# psoc4100smax register map
Vendor: Infineon Technologies; Series: PSOC4100Smax; File version: 1.0
CPU: CM0PLUS r0p1, little endian, MPU, no FPU, VTOR, 2 interrupt priority bits, 32 interrupts
Registers are 32-bit, read-write, reset 0x0 unless marked. A register's access mark holds for its fields unless they carry their own. Offsets are from the block's base; [hi:lo] are bit positions; lines under a group give offsets from that group; {n}, {i} and the like mark numbered series; 'fields as' and 'values as' point back to an identical list; <NAME> marks a mode.

## MSC0 (part 2 of 2) — MultiSense Controller
Base 0x40290000
Same registers: MSC1 0x402A0000
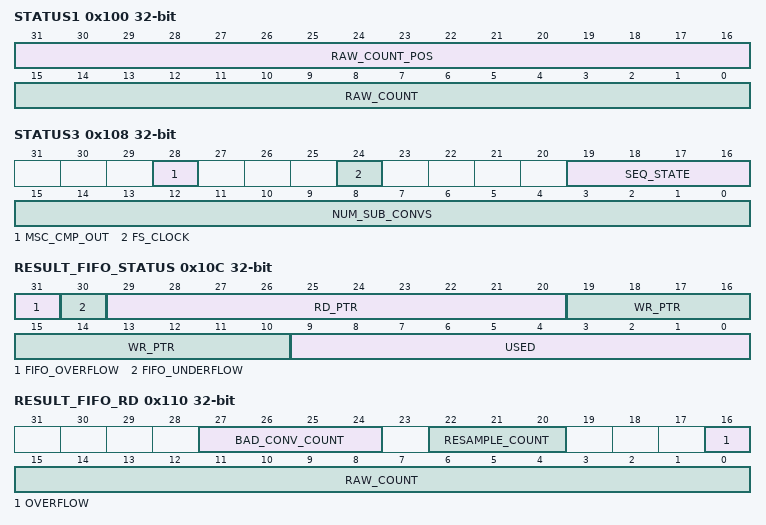
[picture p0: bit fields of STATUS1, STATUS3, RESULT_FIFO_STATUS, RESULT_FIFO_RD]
0x100 STATUS1 ro — General Status Register 1
  [31:16] RAW_COUNT_POS — Useful for determining component counts for positive and negative charge by subtracting from RAW_COUNT. When PHASE_MODE_SEL = FOUR_PHASE RAW_COUNT_POS: Counts during ph1/ph2 of SUB_CONV. When PHASE_MODE_SEL = TWO_PHASE RAW_COUNT_POS: Counts during ph0 of SUB_CONV. This counter increments whenever the Cref CAPDAC is balancing during the corresponding phases above. Note that digital non-overlap is ignored for the purposes of this count since balancing occurs irrespective of these settings. Hence the 'raw' phases (pre application of any digital non-overlap) are considered as the measurement window for this counter. Applicable for CIC1 and CIC2 mode. In CIC2 mode the count is determined by the value of the input to the first integrator stage (equivalent to CIC1 behaviour).
  [15:0] RAW_COUNT — Live current raw counter. For debug/test purposes. In normal operation, Firmware/DMA will typically read results from RESULT_FIFO_RD. Note that in CIC2 mode, this value gets updated at the decimation rate. When the SUB_SAMPLE interrupt is asserted, firmware could read this value before the next SUB_SAMPLE interrupt fires to debug sub-samples if desired.
0x104 STATUS2 ro — General Status Register 2
  [15:0] DEBUG_CONV_COUNT — Debug raw count for a particular conversion. Enabled only during a specified conversion of a sample (a specific chop phase). Only applicable for CIC1 mode. In CIC2 mode this counter remains zero.
0x108 STATUS3 ro — General Status Register 3
  [28] MSC_CMP_OUT — Output of main sensing comparator (synchronized). For debug/test purposes.
  [24] FS_CLOCK — Sense clock Fs control waveform. For debug/test purposes.
  [19:16] SEQ_STATE — MSC Sequencer FSM state.
    0=IDLE (N/A); 1=WAIT_DMA_WRITE (N/A); 2=LOAD_CONFIG (N/A); 3=WAIT_SCAN_START (N/A); 4=ASSERT_RDY (N/A); 5=WAIT_CONSENSUS (N/A); 6=INIT_CMOD (N/A); 7=INIT_SHORT (N/A); 8=PRO_OFFSET (N/A); 9=PRO_DUMMY (N/A); 10=PRO_WAIT (N/A); 11=SUB_CONV (N/A); 12=EPILOGUE (N/A); 13=WAIT_DMA_READ_NEW_SAMPLE (N/A); 14=WAIT_DMA_READ_EOF (N/A); 15=POST_SCAN (N/A)
  [15:0] NUM_SUB_CONVS — Number of sub-conversions remaining while in PRO_DUMMY and SUB_CONV.
0x10C RESULT_FIFO_STATUS ro
  [31] FIFO_OVERFLOW — Set if hardware attempts to write a RAW_COUNT (and associated metrics) to an already full result FIFO.
  [30] FIFO_UNDERFLOW — Hardware sets this field to '1', when reading from an empty FIFO (RESULT_FIFO_STATUS.USED is '0').
  [29:20] RD_PTR — Result FIFO read pointer: FIFO location from which data is read via AHB. Note: This functionality is intended for debugging purposes.
  [19:10] WR_PTR — Result FIFO write pointer: FIFO location at which a new data is written by the hardware. Note: This functionality is intended for debugging purposes.
  [9:0] USED — Number of used/occupied entries in the result FIFO. When '0', the FIFO is empty.
0x110 RESULT_FIFO_RD ro — Result FIFO Pointer
  [27:24] BAD_CONV_COUNT — Counter to indicate whether conversion of a sample is bad at the end of each chop phase. This is true if the comparator has not tripped by the end of EPILOGUE in a chop phase. BAD_CONV_COUNT can have a maximum value of 8 (based on largest legal NUM_CONV). If RESAMPLE_COUNT > 0 and BAD_CONV_COUNT = 0, this indicates that RESAMPLE_COUNT bad samples were encountered before this good sample was obtained. If RESAMPLE_COUNT > 0 and BAD_CONV_COUNT > 0, this indicates that all NUM_AUTO_RESAMPLE attempts have been executed and the final attempt had BAD_CONV_COUNT bad conversions. In this situation RESAMPLE_COUNT should equal NUM_AUTO_RESAMPLE.
  [22:20] RESAMPLE_COUNT — Counter indicating number of attempted re-samples (via NUM_AUTO_RESAMPLE) for this raw count. If RESAMPLE_COUNT = 0 and NUM_AUTO_RESAMPLE > 0, this raw count was obtained from the first sample attempt.
  [16] OVERFLOW — RAW_COUNT overflow.
  [15:0] RAW_COUNT — FILTER_MODE = CIC1: Accumulated raw count for a sample. FILTER_MODE = CIC2: Average value of all valid sub-samples over all conversions in a sample. Note that the hardware averaging capabilities are limited. See INTR.CIC2_ERROR - if this interrupt asserts it *may* be possible to firmware back calculate the correct average. See SCAN_CTL1.RAW_COUNT_MODE for overflow behaviour of RAW_COUNT.
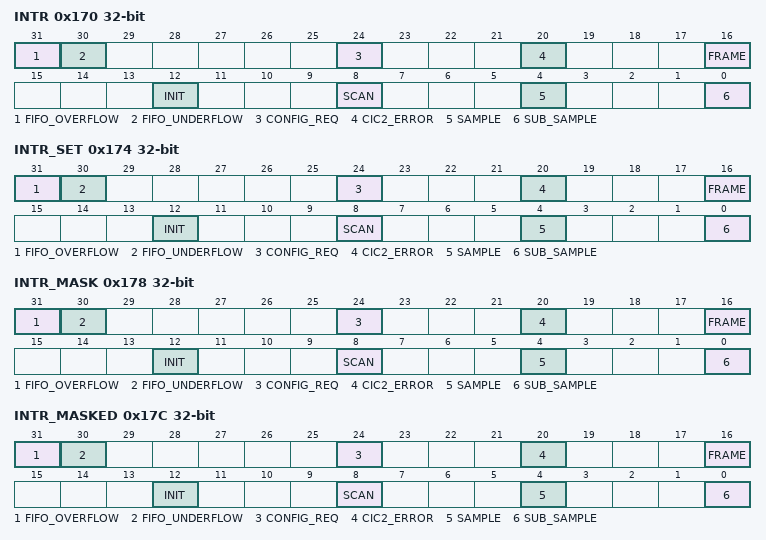
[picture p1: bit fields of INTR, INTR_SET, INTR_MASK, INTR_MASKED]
0x170 INTR — MSCv3 Interrupt Cause Register
  [31] FIFO_OVERFLOW write-1-clears — Result FIFO overflow condition.
  [30] FIFO_UNDERFLOW write-1-clears — Result FIFO underflow condition.
  [24] CONFIG_REQ write-1-clears — Request for scan configuration and scan start. The Sequencer FSM is entering WAIT_SCAN_START when this interrupt is raised. This interrupt can be used in CPU mode in a multi-channel scenario with external frame start to indicate to firmware that it is required to configure the channel and start a scan.
  [20] CIC2_ERROR write-1-clears — CIC2 error detected. This bit is set at the end of a sample if the number of valid CIC2 sub-samples is not one of [1,2,4,8,16]. At the end of a CIC2 sample, RESULT_FIFO_RD.RAW_COUNT contains the average of the valid sub-samples observed during that sample. The average is computed by a power of 2 shift as per below for the number of valid CIC2 samples observed: 0,1 -> no division (not a typical use case since an average of multiple sub-samples is desired) 2 -> divide by 2 3,4 -> divide by 4 5,6,7,8 -> divide by 8 9+ -> divide by 16 The RESULT_FIFO_RD.RAW_COUNT value is only the true average if the number of valid CIC2 sub-samples is [1,2,4,8,16]. However, in the cases of [3.4.5.6.9.10,11,12,13,14,15] firmware can back-calculate the real average from the computed average (RAW_COUNT) and the divisor used to compute that average (1,2,4,8,16 above) as follows assuming the number of valid sub-samples is known: Real_Average = Computed_Average*(Computed_Divider/NumSubSamples) If the number of sub-samples exceeds 16, this cannot be reliably computed due to internal hardware overflows.
  [16] FRAME write-1-clears — A single frame is complete.
  [12] INIT write-1-clears — Coarse initialisation complete. For debug purposes.
  [8] SCAN write-1-clears — A single scan is complete.
  [4] SAMPLE write-1-clears — A single sample is complete. For debug purposes.
  [0] SUB_SAMPLE write-1-clears — A valid CIC2 sub-sample is complete. To facilitate firmware averaging of sub-samples. For debug purposes.
0x174 INTR_SET — MSCv3 Interrupt Set Register
  [31] FIFO_OVERFLOW write-1-sets — Write with '1' to set corresponding bit in interrupt request register (a write of '0' has no effect).
  [30] FIFO_UNDERFLOW write-1-sets — Write with '1' to set corresponding bit in interrupt request register (a write of '0' has no effect).
  [24] CONFIG_REQ write-1-sets — Write with '1' to set corresponding bit in interrupt request register (a write of '0' has no effect).
  [20] CIC2_ERROR write-1-sets — Write with '1' to set corresponding bit in interrupt request register (a write of '0' has no effect).
  [16] FRAME write-1-sets — Write with '1' to set corresponding bit in interrupt request register (a write of '0' has no effect).
  [12] INIT write-1-sets — Write with '1' to set corresponding bit in interrupt request register (a write of '0' has no effect).
  [8] SCAN write-1-sets — Write with '1' to set corresponding bit in interrupt request register (a write of '0' has no effect).
  [4] SAMPLE write-1-sets — Write with '1' to set corresponding bit in interrupt request register (a write of '0' has no effect).
  [0] SUB_SAMPLE write-1-sets — Write with '1' to set corresponding bit in interrupt request register (a write of '0' has no effect).
0x178 INTR_MASK — MSCv3 Interrupt Mask Register
  [31] FIFO_OVERFLOW — Mask bit for corresponding bit in interrupt cause register.
  [30] FIFO_UNDERFLOW — Mask bit for corresponding bit in interrupt cause register.
  [24] CONFIG_REQ — Mask bit for corresponding bit in interrupt cause register.
  [20] CIC2_ERROR — Mask bit for corresponding bit in interrupt cause register.
  [16] FRAME — Mask bit for corresponding bit in interrupt cause register.
  [12] INIT — Mask bit for corresponding bit in interrupt cause register.
  [8] SCAN — Mask bit for corresponding bit in interrupt cause register.
  [4] SAMPLE — Mask bit for corresponding bit in interrupt cause register.
  [0] SUB_SAMPLE — Mask bit for corresponding bit in interrupt cause register.
0x17C INTR_MASKED ro — MSCv3 Interrupt Masked Register
  [31] FIFO_OVERFLOW — Logical AND of corresponding INTR and INTR_MASK bits.
  [30] FIFO_UNDERFLOW — Logical AND of corresponding INTR and INTR_MASK bits.
  [24] CONFIG_REQ — Logical AND of corresponding INTR and INTR_MASK bits.
  [20] CIC2_ERROR — Logical AND of corresponding INTR and INTR_MASK bits.
  [16] FRAME — Logical AND of corresponding INTR and INTR_MASK bits.
  [12] INIT — Logical AND of corresponding INTR and INTR_MASK bits.
  [8] SCAN — Logical AND of corresponding INTR and INTR_MASK bits.
  [4] SAMPLE — Logical AND of corresponding INTR and INTR_MASK bits.
  [0] SUB_SAMPLE — Logical AND of corresponding INTR and INTR_MASK bits.
0x180 INTR_LP — Low Power Interrupt Cause Register
  [0] WAKEUP write-1-clears — LP-AoC has detected wakeup.
0x184 INTR_LP_SET — Low Power Interrupt Set Register
  [0] WAKEUP write-1-sets — Write with '1' to set corresponding bit in interrupt request register (a write of '0' has no effect).
0x188 INTR_LP_MASK — Low Power Interrupt Mask Register
  [0] WAKEUP — Mask bit for corresponding bit in interrupt cause register.
0x18C INTR_LP_MASKED ro — Low Power Interrupt Masked Register
  [0] WAKEUP — Logical AND of corresponding INTR_LP and INTR_LP_MASK bits.
0x190 FRAME_CMD — Frame Command Register
  [0] START_FRAME write-1-sets — Start the MSCv3 sequencer frame process. Note that a rising edge on this bit also creates a 2x cycle clk_msc pulse on the msc_ext_frm_start_out signal. The corresponding msc_ext_frm_start_out_en is controlled by CTL.ENABLED. Sequencer FSM clears this bit on egress from IDLE. If START_FRAME is set by firmware when FSM is not in IDLE, the hardware must hold the bit set to allow for 'pending' frame behaviour. Firmware Rule: Note if FRAME_CMD is used in a multi-channel scenario care must be taken by firmware not to excessively delay FRAME_CMD to each individual channel. If not, a window exists where the first channel that sees FRAME_CMD can reach the WAIT_CONSENSUS state and mistakenly believe all channels are ready for lockstep scanning when the reality is the other channels are still in IDLE and indicating ready because they haven't been initiated yet.
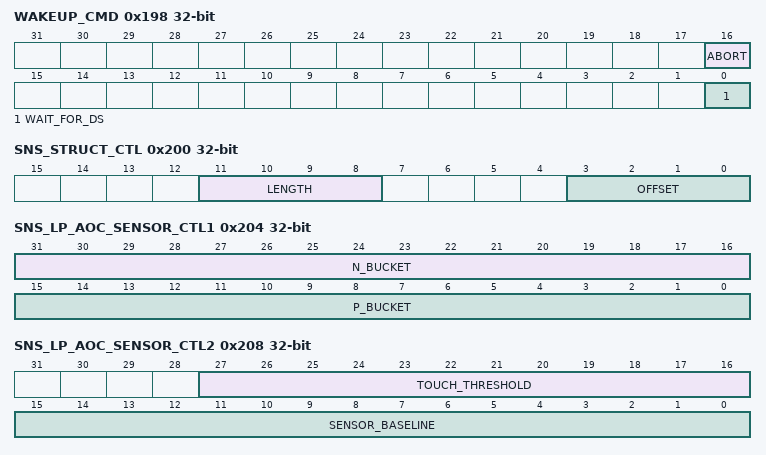
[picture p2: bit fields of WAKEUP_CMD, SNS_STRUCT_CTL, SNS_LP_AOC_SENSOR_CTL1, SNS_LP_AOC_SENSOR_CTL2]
0x198 WAKEUP_CMD — Wakeup Command Register
  [16] ABORT write-1-clears — Abort the LP-AoC when in WAIT_FOR_DS state.
  [0] WAIT_FOR_DS write-1-sets — Set by firmware to prime the LP-AoC FSM to be ready to detect entry to DEEP_SLEEP. When detected, hardware clears the bit down and the LP-AoC FSM periodically scans all valid sensor configurations programmed in the sensor configuration storage starting from FRAME_START_PTR.
0x200 SNS_STRUCT_CTL — Sensor Struct Control
  [11:8] LENGTH — Number of SNS_* registers from OFFSET for current sensor configuration in local IP storage. Used by LOAD_CONFIG state in Sequencer FSM. Applicable only when CONFIG_NR > 0.
  [3:0] OFFSET — Starting offset into SNS_* registers of current sensor configuration in local IP storage. Used by LOAD_CONFIG state in Sequencer FSM. Applicable only when CONFIG_NR > 0.
0x204 SNS_LP_AOC_SENSOR_CTL1 — LP-AoC Sensor Control 1
  [31:16] N_BUCKET — Per sensor bucket for baseline <= raw count adjustments.
  [15:0] P_BUCKET — Per sensor bucket for baseline greater than raw count adjustments.
0x208 SNS_LP_AOC_SENSOR_CTL2 — LP-AoC Sensor Control 2
  [27:16] TOUCH_THRESHOLD — Per sensor threshold for |baseline - rawCount| to warrant a single touch detect.
  [15:0] SENSOR_BASELINE — Per sensor baseline value.
0x20C SNS_SW_SEL_CSW_MASK2 — Control MUX Function Select Mask 2
  [31:0] FUNC_MASK — {SNS_SW_SEL_CSW_MASK2.FUNC_MASK[x], SNS_SW_SEL_CSW_MASK1.FUNC_MASK[x], SNS_SW_SEL_CSW_MASK0.FUNC_MASK[x]} used to select appropriate SW_SEL_CSW_FUNC[x] when CSW_FUNC_MODE[x] = 1.
0x210 SNS_SW_SEL_CSW_MASK1 — Control MUX Function Select Mask 1
  fields as SNS_SW_SEL_CSW_MASK2
0x214 SNS_SW_SEL_CSW_MASK0 — Control MUX Function Select Mask 0
  fields as SNS_SW_SEL_CSW_MASK2
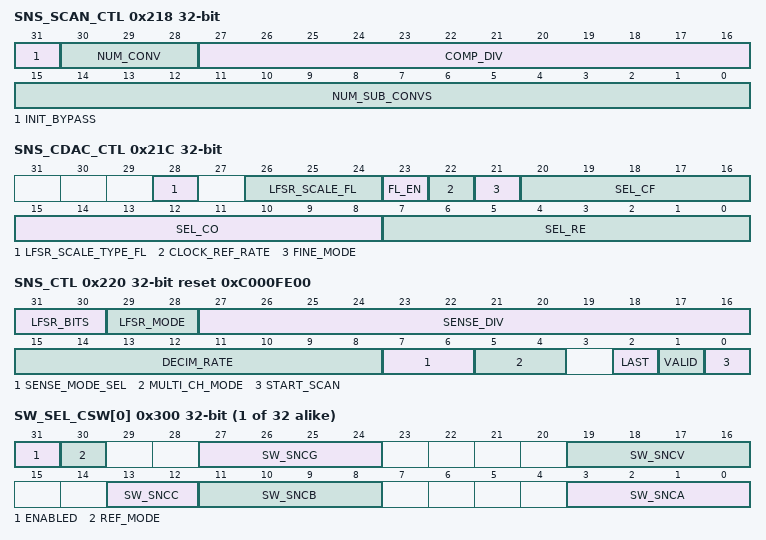
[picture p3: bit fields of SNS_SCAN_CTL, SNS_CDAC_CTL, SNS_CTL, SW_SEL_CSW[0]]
0x218 SNS_SCAN_CTL — Sensor Scan Control
  [31] INIT_BYPASS — Coarse initialisation bypass control. Applies to CMOD_SEL selected Cmod.
    0=DISABLED (N/A); 1=ENABLED (N/A)
  [30:28] NUM_CONV — Number of conversions (minus 1) per scanned sample. This is required for chopping (chop polarity is updated per conversion). Firmware Rule: If chopping is enabled (NUM_CONV > ONE), then NUM_PRO_WAIT_CYCLES must be >=1 and NUM_PRO_DUMMY_SUB_CONVS must be >=1.
    0=ONE (N/A); 1=TWO (N/A); 3=FOUR (N/A); 7=EIGHT (N/A)
  [27:16] COMP_DIV — The ratio (minus 1) of clk_comp::clk_mod. Notes for tuning: Fs = Fmod / Kref Fcomp = Kcomp * Fs MSCv3 MMIO provides: Kref = (SENSE_DIV+1) Fs = Fmod/(SENSE_DIV+1) Fcomp = Fmod / (COMP_DIV+1) Therefore: Kcomp = Fmod/[Fs*(COMP_DIV+1)] Kcomp = (SENSE_DIV+1)/(COMP_DIV+1) It is expected that Kcomp be programmed as an integer. Anything else is considered a mis-programming.
  [15:0] NUM_SUB_CONVS — Number of sub-conversions (minus 1) in a conversion.
0x21C SNS_CDAC_CTL — Sensor CAPDAC Control
  [28] LFSR_SCALE_TYPE_FL — Flatspot/Dither CAPDAC shift direction.
    0=RIGHT (N/A); 1=LEFT (N/A)
  [26:24] LFSR_SCALE_FL — Shift the magnitude portion of the Flatspot/Dither CAPDAC LFSR output code left or right by LSFR_SCALE_FL bits. Direction of shift controlled by LFSR_SCALE_TYPE_FL. Note since the magnitude is 7-bits, the maximum shift is 6-bits. The sign bit does not form part of the shift. Example: 6-bit polynomial (x^6 + x^4 + x^3 + x^2 + 1). lfsr_fl_out[7] = lfsr_fl[5]; // Sign bit always connected in MSB to HardIP. if(LFSR_SCALE_TYPE_FL == LEFT) lfsr_out[6:0] = {2'b00,lfsr[4:0]} << LFSR_SCALE_FL; // Scaled 7-bit magnitude. else lfsr_out[6:0] = {2'b00,lfsr[4:0]} >> LFSR_SCALE_FL; // Scaled 7-bit magnitude.
    6=MAX (N/A)
  [23] FL_EN — Dither/Flatspot LFSR enable control. '0': Dither/Flatspot LFSR is disabled. LFSR_SCALE_FL, LFSR_SCALE_TYPE_FL and ACTIVATION_MODE and MSB manipulation logic have no effect. The hard IP is presented with the code programmed into SEL_FL. '1': The Dither/Flatspot LFSR is enabled.
    0=DISABLED (N/A); 1=ENABLED (N/A)
  [22] CLOCK_REF_RATE — Used to select clk_mod or clk_mod/2 to as clk_ref. This clock is gated depending on the synchronised comparator to generate the gated feedback clock (clk_reffb) to the Reference CAPDAC. '0': Use clk_mod. '1': Use clk_mod/2.
    0=CLK_MOD (N/A); 1=HALF_CLK_MOD (N/A)
  [21] FINE_MODE — Operational mode for Fine CAPDAC
    0=REFERENCE (N/A); 1=COMPENSATION (N/A)
  [20:16] SEL_CF — Select value for Fine CAPDAC size.
  [15:8] SEL_CO — Select value for Compensation CAPDAC size. Note if SEL_CO = 0 and FINE_MODE != COMPENSATION, then clk_comp is gated during PRO_DUMMY, SUB_CONV and EPILOGUE.
  [7:0] SEL_RE — Select value for Reference CAPDAC size.
0x220 SNS_CTL reset 0xC000FE00 — Sense Control and Command Register
  [31:30] LFSR_BITS — Selects the number of LSB bits to use from the LSFR to provide the clock dithering variation on the base period (spread spectrum mode). Caveat make sure that SENSE_DIV > the maximum absolute range (e.g. for 4B SENSE_DIV > 8), otherwise results are undefined.
    0=2B (Use 2 bits: range = [-2,1]); 1=3B (Use 3 bits: range = [-4,3]); 2=4B (Use 4 bits: range = [-8,7]); 3=5B (Use 5 bits: range = [-16,15] (default))
  [29:28] LFSR_MODE — Mode for generating the sense clock. '0': Direct Clocking. '1': Spread Spectrum. '2': PRS.
    0=DIRECT_CLOCK (N/A); 1=SPREAD_SPECTRUM (N/A); 2=PRS (N/A)
  [27:16] SENSE_DIV — The length (minus 1) of the sense modulation 'clock' period in clk_mod cycles (frequency = Fs). SENSE_DIV + 1 = sense_ratio. Note this is the base divider, clock dithering may change the actual period length. Firmware Rule: Firmware is responsible for programming a value in this register to ensure correct operation. When LFSR_MODE = DIRECT_CLOCK, in 2-phase mode sense_ratio needs to be >=4 to allow for digital non-overlap. In 4-phase mode, sense_ratio needs to be >=8. If spread spectrum is enabled (LFSR_MODE = SPREAD_SPECTRUM), SENSE_DIV must be programmed large enough to ensure that negative dithering does not cause sense_ratio to become too small. It is possible for SENSE_DIV to be as low as zero though when LFSR_MODE = PRS (if digital non-overlap is disabled). This is because in PRS mode, SENSE_DIV defines the rate at which the LFSR is clocked and the MSB of the LFSR is used to create the phase signals.
  [15:8] DECIM_RATE — Sets the decimation rate for the sinc^2 filter (CIC2). Typically referred to as N. Note N = DECIM_RATE + 1. Only applies when FILTER_CTL.FILTER_MODE = CIC2, and irrelevant for CIC1 mode (no effect in this mode). Maximum value out of CIC2 is N^2 (unsigned input) and +/- N^2 (signed input). Since CIC2 uses a 16-bit pipeline, the maximum range is [0,2^16-1] (unsigned) and [-2^15,2^15-1] (signed). This implies a limitation on maximum usable DECIM_RATE depending on BIT_FORMAT signed/unsigned. BIT_FORMAT = UNSIGNED -> DECIM_RATE(max) = 254 (N = 255). BIT_FORMAT = SIGNED -> DECIM_RATE(max) = 180 (N = 181). The scan time for M-bit scan is 2^M clk_mod cycles. This value is determined by (SENSE_DIV+1)*(NUM_SUB_CONVS+1). Note that the CIC2 filter does not operate in the EPILOGUE state, so NUM_EPI_CYCLES does not feed into the above equation.
  [7:6] SENSE_MODE_SEL — Sense mode register structure selection. This field allows quick change between registers that influence sense mode. This register selects which structure is currently 'live' and used by the IP. These registers are captured in MODE_STRUCT. The usable values in this register is determined by design time parameter SENSE_MODE_NR.
    {v}=SENSE_MODE_{v} (Use MODE_STRUCT[{v}].) (v=0..3)
  [5:4] MULTI_CH_MODE — Multi channel mode configuration. Determines whether consensus mechanism is engaged to ensure channels scan in lockstep. '0': Single channel. '1': Wait for external sync (off-chip). '2': Wait for internal sync (on-chip).
    0=OFF (N/A); 1=EXTERNAL (N/A); 2=INTERNAL (N/A)
  [2] LAST — Indicator that current sensor configuration is the last sensor in the frame.
  [1] VALID — Indicator of sensor configuration validity.
  [0] START_SCAN write-1-sets — Start the MSCv3 sequencer scan process. The sequencer will clear this bit when it is done. Depending on the mode the sequencer is done when all NUM_SAMPLES for this scan have been accumulated, or if the sequencer is reset.
{0x300+4i} SW_SEL_CSW[{i}] (i=0..31) — Control Switch MUX Switch Control
  [31] ENABLED — Control MUX Sensor N enable. Firmware Rule: 1) If any of SNCA/SNCB/SNCC can be 1 (statically or dynamically), ENABLED must be 1. 2) If statically closing (using CLOSED setting) any of SNCA/SNCB/SNCC, ENABLE must be set to 1 in a previous bus access to ensure break-before-make. When re-opening from static CLOSED, SNCA/SNCB/SNCC must be opened in a previous bus access before clearing ENABLE to 0. This is not required for dynamic programming options since e.g. PH0 is not active when these registers are programmed. 3) In any use case where SNCA/SNCB/SNCC are required to be set CLOSED via autonomous scanning, rule (2) cannot be observed. Example use case below**. In this scenario to get the desired effect, the options are to either: a) Dedicate a specific CSW sensor for this purpose, follow rule (2) and do not change the settings autonomously for this sensor. b) Use unused Cmod switches (e.g. if Cmod1/2 are being used, use the switches for Cmod3/4). ** Any use case where a csdbusa/b/c is not used. For example FW CSX wherein csdbusc not used; then csdbusc is statically connected to vssa_sc (SNCG=CLOSED, ENABLED=1 and SNCC=CLOSED).
    0=DISABLED (N/A); 1=ENABLED (N/A)
  [30] REF_MODE — Control MUX Sensor N is used as a reference.
    0=DISABLED (N/A); 1=ENABLED (N/A)
  [27:24] SW_SNCG — Control MUX Sensor N to vssa_q Switch. Firmware Rule: Do not program SNCV and SNCG such that they are closed simultaneously.
    0=OPEN (N/A); 1=CLOSED (N/A); 2=PH0 (N/A); 3=PH1 (N/A); 4=PH2 (N/A); 5=PH1_OR_PH3 (N/A); 6=PH2_OR_PH3 (N/A); 7=PH0X (N/A); 8=PH1X (N/A); 9=PH2_OR_FS2PH1_AND_PH1_OR_PH3 (ph2 || [Fs2_ph1 && (ph1 || ph3)]); 10=CLK_BAR (clk_extfb_bar)
  [19:16] SW_SNCV — Control MUX Sensor N to vdda_q Switch. Firmware Rule: Do not program SNCV and SNCG such that they are closed simultaneously.
    0=OPEN (N/A); 1=CLOSED (N/A); 2=PH0 (N/A); 3=PH1 (N/A); 4=PH2 (N/A); 5=PH0_OR_PH1 (N/A); 6=PH0X (N/A); 7=PH1X (N/A); 8=PH0_OR_FS2PH0_AND_PH1_OR_PH3 (ph0 || [Fs2_ph0 && (ph1 || ph3)]); 9=CLK (clk_extfb)
  [13:12] SW_SNCC — Control MUX Sensor N to CSD Bus C Switch. Firmware Rule: See rule for ENABLED.
    0=OPEN (N/A); 1=CLOSED (N/A); 2=PH1_OR_PH3 (N/A)
  [11:8] SW_SNCB — Control MUX Sensor N to CSD Bus B Switch. Firmware Rule: See rule for ENABLED.
    0=OPEN (N/A); 1=CLOSED (N/A); 2=CHOP_TWO_PHASE (chop == 0 ? ph1 : ph0); 3=CHOP_FOUR_PHASE (chop == 0 ? ph3 : ph1); 4=CHOP_MPSC_D (chop == 0 ? ph1 : ph3); 5=CHOP_MPRX (chop == 0 ? ph0 : ph1); 6=PH0 (N/A); 7=PH2 (N/A); 8=CHOP_CLK_BAR (chop == 0 ? clk_extfb : clk_extfb_bar); 9=CHOP_CLK (chop == 1 ? clk_extfb : clk_extfb_bar)
  [3:0] SW_SNCA — Control MUX Sensor N to CSD Bus A Switch. Firmware Rule: See rule for ENABLED.
    0=OPEN (N/A); 1=CLOSED (N/A); 2=CHOP_TWO_PHASE (chop == 0 ? ph0 : ph1); 3=CHOP_FOUR_PHASE (chop == 0 ? ph1 : ph3); 4=CHOP_MPSC_D (chop == 0 ? ph3 : ph1); 5=CHOP_MPRX (chop == 0 ? ph1 : ph0); 6=PH1 (N/A); 7=PH3 (N/A); 8=CHOP_CLK_BAR (chop == 0 ? clk_extfb : clk_extfb_bar); 9=CHOP_CLK (chop == 1 ? clk_extfb : clk_extfb_bar)
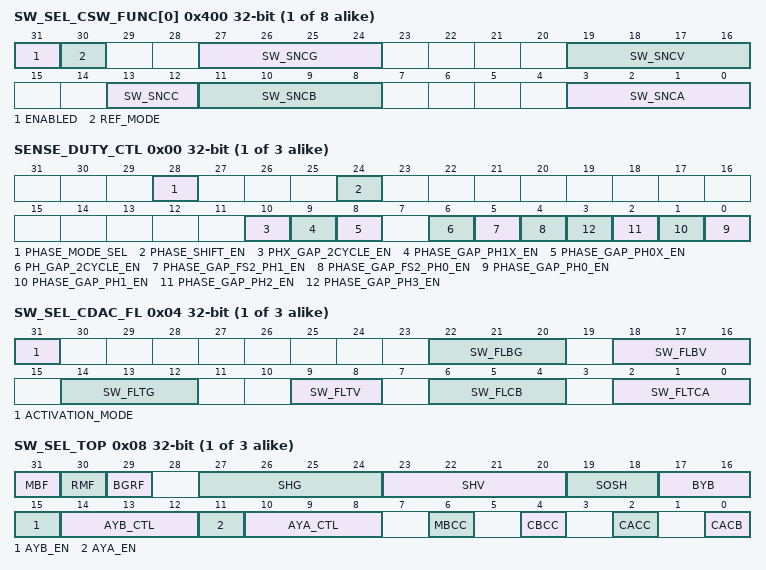
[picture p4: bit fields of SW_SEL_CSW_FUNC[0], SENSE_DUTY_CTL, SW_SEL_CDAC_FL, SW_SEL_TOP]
{0x400+4i} SW_SEL_CSW_FUNC[{i}] (i=0..7) — Control Switch MUX Switch Control Global Functions
  [31] ENABLED — Control MUX Sensor enable.
    0=DISABLED (N/A); 1=ENABLED (N/A)
  [30] REF_MODE — Control MUX Sensor is used as a reference.
    0=DISABLED (N/A); 1=ENABLED (N/A)
  [27:24] SW_SNCG — Control MUX Sensor to vssa_q Switch. Firmware Rule: Do not program SNCV and SNCG such that they are closed simultaneously.
    values as SW_SEL_CSW[0].SW_SNCG
  [19:16] SW_SNCV — Control MUX Sensor to vdda_q Switch. Firmware Rule: Do not program SNCV and SNCG such that they are closed simultaneously.
    values as SW_SEL_CSW[0].SW_SNCV
  [13:12] SW_SNCC — Control MUX Sensor to CSD Bus C Switch. Firmware Rule: See corresponding rule in SW_SEL_CSW.
    0=OPEN (N/A); 1=CLOSED (N/A); 2=PH1_OR_PH3 (N/A)
  [11:8] SW_SNCB — Control MUX Sensor to CSD Bus B Switch. Firmware Rule: See corresponding rule in SW_SEL_CSW.
    values as SW_SEL_CSW[0].SW_SNCB
  [3:0] SW_SNCA — Control MUX Sensor to CSD Bus A Switch. Firmware Rule: See corresponding rule in SW_SEL_CSW.
    values as SW_SEL_CSW[0].SW_SNCA
{0x500+0x20*i} MODE[{i}] (i=0..2) group — Sense Mode Configuration Structure
  0x00 SENSE_DUTY_CTL — Sense Clock Duty Cycle Control
    [28] PHASE_MODE_SEL — Select 4-phase or 2-phase mode. '0': Four phase. '1': Two phase.
      0=FOUR_PHASE (N/A); 1=TWO_PHASE (N/A)
    [24] PHASE_SHIFT_EN — Enable phase shift logic that generates the Ph0X and Ph1X waveforms. Used for inductive and impedance sensing. If enabled, PHASE_SHIFT_CYCLES must be > 0.
      0=DISABLED (N/A); 1=ENABLED (N/A)
    [10] PHX_GAP_2CYCLE_EN — If set, applies a two cycle gap on ph0X/ph1X if the corresponding PHASE_GAP_*_EN is set.
      0=ONE_CYCLE (N/A); 1=TWO_CYCLE (N/A)
    [9] PHASE_GAP_PH1X_EN — Decide whether clk_mod cycle non-overlap gap is applied at the end of ph1x. PHASE_GAP_PH1X_EN = 0 -> No gap. PHASE_GAP_PH1X_EN = 1 && PHX_GAP_2CYCLE_EN = 0 -> 1x cycle gap. PHASE_GAP_PH1X_EN = 1 && PHX_GAP_2CYCLE_EN = 1 -> 2x cycle gap. Does not apply to signals controlled by SW_SEL_CSD and SW_SEL_DSI since GPIO has in-built non-overlap circuitry.
      0=DISABLED (N/A); 1=ENABLED (N/A)
    [8] PHASE_GAP_PH0X_EN — Decide whether clk_mod cycle non-overlap gap is applied at the end of ph0x. PHASE_GAP_PH0X_EN = 0 -> No gap. PHASE_GAP_PH0X_EN = 1 && PHX_GAP_2CYCLE_EN = 0 -> 1x cycle gap. PHASE_GAP_PH0X_EN = 1 && PHX_GAP_2CYCLE_EN = 1 -> 2x cycle gap. Does not apply to signals controlled by SW_SEL_CSD and SW_SEL_DSI since GPIO has in-built non-overlap circuitry.
      0=DISABLED (N/A); 1=ENABLED (N/A)
    [6] PH_GAP_2CYCLE_EN — If set, applies a two cycle gap on ph0/ph1/ph2/ph3/Fs2_ph0/Fs2_ph1 if the corresponding PHASE_GAP_*_EN is set.
      0=ONE_CYCLE (N/A); 1=TWO_CYCLE (N/A)
    [5] PHASE_GAP_FS2_PH1_EN — Decide whether clk_mod cycle non-overlap gap is applied at the end of Fs2_ph0. PHASE_GAP_FS2_PH1_EN = 0 -> No gap. PHASE_GAP_FS2_PH1_EN = 1 && PH_GAP_2CYCLE_EN = 0 -> 1x cycle gap. PHASE_GAP_FS2_PH1_EN = 1 && PH_GAP_2CYCLE_EN = 1 -> 2x cycle gap. Does not apply to signals controlled by SW_SEL_CSD and SW_SEL_DSI since GPIO has in-built non-overlap circuitry.
      0=DISABLED (N/A); 1=ENABLED (N/A)
    [4] PHASE_GAP_FS2_PH0_EN — Decide whether clk_mod cycle non-overlap gap is applied at the end of Fs2_ph0. PHASE_GAP_FS2_PH0_EN = 0 -> No gap. PHASE_GAP_FS2_PH0_EN = 1 && PH_GAP_2CYCLE_EN = 0 -> 1x cycle gap. PHASE_GAP_FS2_PH0_EN = 1 && PH_GAP_2CYCLE_EN = 1 -> 2x cycle gap. Does not apply to signals controlled by SW_SEL_CSD and SW_SEL_DSI since GPIO has in-built non-overlap circuitry.
      0=DISABLED (N/A); 1=ENABLED (N/A)
    [n] PHASE_GAP_PH{n}_EN (n=0..3) — Decide whether clk_mod cycle non-overlap gap is applied at the end of ph{n}. PHASE_GAP_PH{n}_EN = 0 -> No gap. PHASE_GAP_PH{n}_EN = 1 && PH_GAP_2CYCLE_EN = 0 -> 1x cycle gap. PHASE_GAP_PH{n}_EN = 1 && PH_GAP_2CYCLE_EN = 1 -> 2x cycle gap. Does not apply to signals controlled by SW_SEL_CSD and SW_SEL_DSI since GPIO has in-built non-overlap circuitry.
      0=DISABLED (N/A); 1=ENABLED (N/A)
  0x04 SW_SEL_CDAC_FL — Flatspot/Dither CAPDAC Switch Control
    [31] ACTIVATION_MODE — Activation event for Dither/Flatspot LFSR. '0': Clock LFSR on ph0. '1': Clock LFSR on ph0 or ph2. Notes: PH0 activation can be used in both 2 and 4 phase mode (PHASE_MODE_SEL). PH0_OR_PH2 activation can be used in 4 phase mode only (PHASE_MODE_SEL). In PH0 activation mode, the LFSR clocks on ph0 only. However hardware autonomously intervenes by processing the LFSR MSB before routing to the HardIP as follows during any given sense period: PHASE_MODE_SEL = TWO_PHASE: Invert LFSR MSB on ph1 rising edge. PHASE_MODE_SEL = FOUR_PHASE: Invert LFSR MSB on ph2 rising edge.
      0=PH0 (N/A); 1=PH0_OR_PH2 (N/A)
    [22:20] SW_FLBG — Flatspot/Dither CAPDAC bottom plate to vssa_q Switch. Firmware Rule: Do not program FLBV and FLBG such that they are closed simultaneously. Notes: 1) Equations below describe 'msb' term as raw LFSR output, and take into account overriding as defined by ACTIVATION_MODE. 2) Glitches on FLBV or FLBG during ph0 or ph2 are acceptable (if msb toggles at this time) as the FLTCA and FLCB switches are open during this phase so there is no connection into the comparator or the Cmod caps.
      0=OPEN (N/A); 1=CLOSED (N/A); 2=PH0X (N/A); 3=PH1X (N/A); 4=PRECHARGE_2_PH ([(msb^ph1)^(ph0||ph1)] & [ph0||ph1]); 5=PRECHARGE_2_PH_BAR ((![(msb^ph1)^(ph0||ph1)]) & [ph0||ph1]); 6=PRECHARGE_4_PH ([(msb^(ph2||ph3))^(ph0||ph2)] & [ph0||ph1||ph2||ph3]); 7=PRECHARGE_4_PH_BAR ((![(msb^(ph2||ph3))^(ph0||ph2)]) & [ph0||ph1||ph2||ph3])
    [18:16] SW_FLBV — Flatspot/Dither CAPDAC bottom plate to vdda_q Switch. Firmware Rule: Do not program FLBV and FLBG such that they are closed simultaneously. Notes: 1) Equations below describe 'msb' term as raw LFSR output, and take into account overriding as defined by ACTIVATION_MODE. 2) Glitches on FLBV or FLBG during ph0 or ph2 are acceptable (if msb toggles at this time) as the FLTCA and FLCB switches are open during this phase so there is no connection into the comparator or the Cmod caps.
      values as SW_FLBG
    [14:12] SW_FLTG — Flatspot/Dither CAPDAC top plate to vssa_q Switch. Firmware Rule: Do not program FLTV and FLTG such that they are closed simultaneously.
      0=OPEN (N/A); 1=CLOSED (N/A); 2=PH1 (N/A); 3=PH0_OR_PH2 (N/A); 4=PH0 (DFT mode); 5=PH2 (DFT mode)
    [9:8] SW_FLTV — Flatspot/Dither CAPDAC top plate to vdda_q Switch. Firmware Rule: Do not program FLTV and FLTG such that they are closed simultaneously.
      0=OPEN (N/A); 1=CLOSED (N/A); 2=PH0 (DFT mode); 3=PH2 (DFT mode)
    [6:4] SW_FLCB — Flatspot/Dither CAPDAC to CSD Bus B Switch
      0=OPEN (N/A); 1=CLOSED (N/A); 2=CHOP_PH1_4PHASE (chop == 1 ? ph1 : ph3); 3=CHOP_PH3 (chop == 1 ? ph3 : ph1); 4=CHOP_PH0 (chop == 1 ? ph0 : ph1); 5=CHOP_PH1_2PHASE (chop == 1 ? ph1 : ph0)
    [2:0] SW_FLTCA — Flatspot/Dither CAPDAC top plate to CSD Bus A Switch
      values as SW_FLCB
  0x08 SW_SEL_TOP — Top Level Switch Control
    [31] MBF — AMUXBUSB to Filter Switch
      0=OPEN (N/A); 1=CLOSED (N/A)
    [30] RMF — Ratiometric Reference to Filter Switch
      0=OPEN (N/A); 1=CLOSED (N/A)
    [29] BGRF — Bandgap Reference to Filter Switch
      0=OPEN (N/A); 1=CLOSED (N/A)
    [27:24] SHG — COAX Shield to vssa_q Switch
      0=OPEN (N/A); 1=CLOSED (N/A); {v}=PH{v-2} (N/A) (v=2..5); 6=PH0X (N/A); 7=PH1X (N/A); 8=PH0_OR_FS2PH0_AND_PH1_OR_PH3 (ph0 || [Fs2_ph0 && (ph1 || ph3)]); 9=PH2_OR_FS2PH1_AND_PH1_OR_PH3 (ph2 || [Fs2_ph1 && (ph1 || ph3)])
    [23:20] SHV — COAX Shield to vdda_q Switch
      values as SHG
    [19:18] SOSH — COAX Shield to Shield Buffer Output Switch
      0=OPEN (N/A); 1=CLOSED (N/A); 2=PH1_OR_PH3 (N/A)
    [17:16] BYB — AMUXBUS B to CSD Bus B Switch. This register is wired to the hard IP directly (no MUX required in soft IP).
      0=OPEN_ISOLATED (sel = 00); 1=OPEN_NON_ISOLATED_CSDBUS (sel = 01); 2=OPEN_NON_ISOLATED_AMUXBUS (sel = 10); 3=CLOSED (sel = 11)
    [15] AYB_EN — AMUXBUS A to CSD Bus B Switch. Controls first part of AYB switch (AYB_EN<0> on the hardIP). This register is wired to the hard IP directly (no MUX required in soft IP).
      0=OPEN_ISOLATED (Opens first part of AYB switch. Enables isolation on AYB if AYB_CTL is also OPEN.); 1=CLOSED (Closes first part of AYB switch and disables isolation.)
    [14:12] AYB_CTL — AMUXBUS A to CSD Bus B Switch. Controls second part of AYB switch (AYB_EN<1> on hardIP). Alternative to using dsi_csh_tank in GPIO mode.
      0=OPEN (Opens second part of AYB switch. Enables isolation on AYB if AYB_EN is also OPEN_ISOLATED.); 1=CLOSED (N/A); 2=CHOP_TWO_PHASE (chop == 0 ? ph1 : ph0); 3=CHOP_FOUR_PHASE (chop == 0 ? ph3 : ph1); 4=CHOP_MPSC_D (chop == 0 ? ph1 : ph3); 5=CHOP_MPRX (chop == 0 ? ph0 : ph1); 6=PH0 (N/A); 7=PH2 (N/A)
    [11] AYA_EN — AMUXBUS A to CSD Bus A Switch. Controls the first part of AYA switch (AYA_EN<0> on the hardIP). This register is wired to the hard IP directly (no MUX required in soft IP).
      0=OPEN_ISOLATED (Opens first part of AYA switch. Enables isolation on AYA if AYA_CTL is also OPEN.); 1=CLOSED (Closes first part of AYA switch and disables isolation.)
    [10:8] AYA_CTL — AMUXBUS A to CSD Bus A Switch. Controls second part of AYA switch (AYA_EN<1> on hardIP). Alternative to using dsi_cmod in GPIO mode. Note that hardware overrides MMIO setting for AYA and sets it CLOSED during the INIT_SHORT state if using GPIO sensors (SW_DSI_CMOD != OPEN || SW_DSI_CSHTANK != OPEN || AYA_EN == CLOSED || AYB_EN == CLOSED). This register is wired to the hard IP directly (no MUX required in soft IP).
      0=OPEN (Opens second part of AYA switch. Enables isolation on AYA if AYA_EN is also OPEN_ISOLATED.); 1=CLOSED (N/A); 2=CHOP_TWO_PHASE (chop == 0 ? ph0 : ph1); 3=CHOP_FOUR_PHASE (chop == 0 ? ph1 : ph3); 4=CHOP_MPSC_D (chop == 0 ? ph3 : ph1); 5=CHOP_MPRX (chop == 0 ? ph1 : ph0); 6=PH0 (N/A); 7=PH2 (N/A)
    [6] MBCC — AMUXBUSB to CSD Bus C Switch
      0=OPEN (N/A); 1=CLOSED (N/A)
    [4] CBCC — CSD Bus B to CSD Bus C Switch
      0=OPEN (N/A); 1=CLOSED (N/A)
    [2] CACC — CSD Bus A to CSD Bus C Switch
      0=OPEN (N/A); 1=CLOSED (N/A)
    [0] CACB — CSD Bus A to CSD Bus B Switch. Note that hardware overrides MMIO setting for CACB and sets it CLOSED during the INIT_SHORT state if using GPIO sensors (SW_DSI_CMOD != OPEN || SW_DSI_CSHTANK != OPEN || AYA_EN == CLOSED || AYB_EN == CLOSED).
      0=OPEN (N/A); 1=CLOSED (N/A)
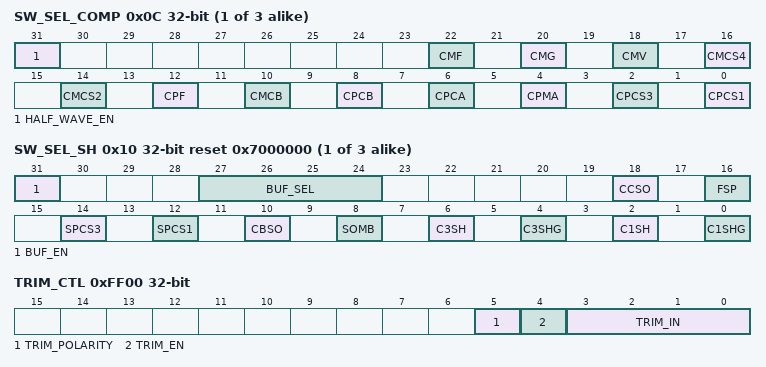
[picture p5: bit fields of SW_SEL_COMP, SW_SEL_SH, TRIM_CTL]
  0x0C SW_SEL_COMP — MSC Comparator Switch Control
    [31] HALF_WAVE_EN — Enables halfwave mode in the comparator where reference is vdda_q. Firmware Rule: When HALF_WAVE_EN = ENABLED, CHOP_POL must be programmed to 1 in the case where INIT_MODE = REFERENCE_VDDA.
      0=DISABLED (N/A); 1=ENABLED (N/A)
    [22] CMF — Comparator Minus Terminal to Reference Filter Switch
      0=OPEN (N/A); 1=CLOSED (N/A)
    [20] CMG — Comparator Minus Terminal to vssa_q Switch. Firmware Rule: Do not program CMV and CMG such that they are closed simultaneously.
      0=OPEN (N/A); 1=CLOSED (N/A)
    [18] CMV — Comparator Minus Terminal to vdda_q Switch. Firmware Rule: Do not program CMV and CMG such that they are closed simultaneously.
      0=OPEN (N/A); 1=CLOSED (N/A)
    [16] CMCS4 — Comparator Minus Terminal to CMOD4 Sense Switch
      0=OPEN (N/A); 1=CLOSED (N/A)
    [14] CMCS2 — Comparator Minus Terminal to CMOD2 Sense Switch
      0=OPEN (N/A); 1=CLOSED (N/A)
    [12] CPF — Comparator Plus Terminal to Reference Filter Switch
      0=OPEN (N/A); 1=CLOSED (N/A)
    [10] CMCB — Comparator Minus Terminal to CSD Bus B Switch
      0=OPEN (N/A); 1=CLOSED (N/A)
    [8] CPCB — Comparator Plus Terminal to CSD Bus B Switch
      0=OPEN (N/A); 1=CLOSED (N/A)
    [6] CPCA — Comparator Plus Terminal to CSD Bus A Switch
      0=OPEN (N/A); 1=CLOSED (N/A)
    [4] CPMA — Comparator Plus Terminal to AMUXBUSA Switch
      0=OPEN (N/A); 1=CLOSED (N/A)
    [2] CPCS3 — Comparator Plus Terminal to CMOD3 Sense Switch
      0=OPEN (N/A); 1=CLOSED (N/A)
    [0] CPCS1 — Comparator Plus Terminal to CMOD1 Sense Switch
      0=OPEN (N/A); 1=CLOSED (N/A)
  0x10 SW_SEL_SH reset 0x7000000 — Shielding Switch Control
    [31] BUF_EN — Enable the shield buffer. '0': Off '1': On
      0=DISABLED (N/A); 1=ENABLED (N/A)
    [27:24] BUF_SEL — Selects value of compensation capacitance in shield buffer.
    [18] CCSO — CSD Bus C to Shield OpAmp Switch
      0=OPEN (N/A); 1=CLOSED (N/A)
    [16] FSP — Reference Filter to Shield Positive Terminal Switch
      0=OPEN (N/A); 1=CLOSED (N/A)
    [14] SPCS3 — Shield Positive Terminal to CMOD3 Sense Switch
      0=OPEN (N/A); 1=CLOSED (N/A)
    [12] SPCS1 — Shield Positive Terminal to CMOD1 Sense Switch
      0=OPEN (N/A); 1=CLOSED (N/A)
    [10] CBSO — CSD Bus B to Shield OpAmp Switch
      0=OPEN (N/A); 1=CLOSED (N/A)
    [8] SOMB — Shield OpAmp to AMUXBUSB Switch
      0=OPEN (N/A); 1=CLOSED (N/A)
    [6] C3SH — cmod3_4_sh to sh Switch (Drives cmod3_4_sh with shield signal)
      0=OPEN (N/A); 1=CLOSED (N/A)
    [4] C3SHG — cmod3_4_sh to vssa Switch
      0=OPEN (N/A); 1=CLOSED (N/A)
    [2] C1SH — cmod1_2_sh to sh Switch (Drives cmod1_2_sh with shield signal)
      0=OPEN (N/A); 1=CLOSED (N/A)
    [0] C1SHG — cmod1_2_sh to vssa Switch
      0=OPEN (N/A); 1=CLOSED (N/A)
{0x1000+4i} SENSOR_DATA[{i}] (i=0..4095) — Sensor Configuration Storage
  [31:0] DATA — Local IP storage to support per-sensor configuration for AS-MS mode. Storage requirement in bytes is CONFIG_NR * (number of per sensor registers) * 4. The per sensor registers all have the prefix SNS_*.
0xFF00 TRIM_CTL — Trim Control
  [5] TRIM_POLARITY — Controls polarity of comparator offset trim.
  [4] TRIM_EN — Enables comparator offset trim.
    0=DISABLED (N/A); 1=ENABLED (N/A)
  [3:0] TRIM_IN — Controls magnitude of comparator offset trim.

## Notices in the file
(c) 2016-2026, Infineon Technologies AG or an affiliate of
Infineon Technologies AG.
SPDX-License-Identifier: Apache-2.0
Licensed under the Apache License, Version 2.0 (the "License");
you may not use this file except in compliance with the License.
You may obtain a copy of the License at
http://www.apache.org/licenses/LICENSE-2.0
Unless required by applicable law or agreed to in writing, software
distributed under the License is distributed on an "AS IS" BASIS,
WITHOUT WARRANTIES OR CONDITIONS OF ANY KIND, either express or implied.
See the License for the specific language governing permissions and
limitations under the License.
